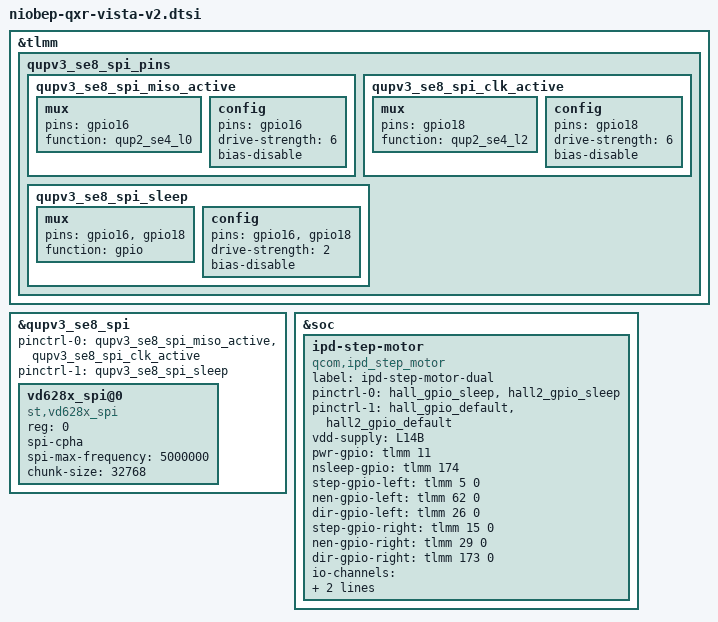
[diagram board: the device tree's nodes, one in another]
#include "niobep-qxr-vista.dtsi"

&tlmm {

	/delete-node/ qupv3_se8_spi_pins;

	qupv3_se8_spi_pins: qupv3_se8_spi_pins {
		qupv3_se8_spi_miso_active: qupv3_se8_spi_miso_active {
			mux {
				pins = "gpio16";
				function = "qup2_se4_l0";
			};

			config {
				pins = "gpio16";
				drive-strength = <6>;
				bias-disable;
			};
		};

		qupv3_se8_spi_clk_active: qupv3_se8_spi_clk_active {
			mux {
				pins = "gpio18";
				function = "qup2_se4_l2";
			};

			config {
				pins = "gpio18";
				drive-strength = <6>;
				bias-disable;
			};
		};

		qupv3_se8_spi_sleep: qupv3_se8_spi_sleep {
			mux {
				pins = "gpio16","gpio18";
				function = "gpio";
			};

			config {
				pins = "gpio16","gpio18";
				drive-strength = <2>;
				bias-disable;
			};
		};
	};
};

&qupv3_se8_spi {
	/delete-property/ pinctrl-1;
	/delete-property/ pinctrl-0;
	pinctrl-0 = <&qupv3_se8_spi_miso_active>, <&qupv3_se8_spi_clk_active>;
	pinctrl-1 = <&qupv3_se8_spi_sleep>;
};
&soc {
	/delete-node/ ipd-step-motor;

	ipd-step-motor {
		status = "ok";
		compatible = "qcom,ipd_step_motor";
		label = "ipd-step-motor-dual";

		pinctrl-names = "sleep", "default";
		pinctrl-0 = <&hall_gpio_sleep &hall2_gpio_sleep>;
		pinctrl-1 = <&hall_gpio_default &hall2_gpio_default>;
		vdd-supply = <&L14B>;

		pwr-gpio = <&tlmm 11  0>;
		nsleep-gpio = <&tlmm 174  0>;

		step-gpio-left = <&tlmm 5  0>;
		nen-gpio-left = <&tlmm 62 0>;
		dir-gpio-left = <&tlmm  26 0>;

		step-gpio-right = <&tlmm 15  0>;
		nen-gpio-right = <&tlmm 29 0>;
		dir-gpio-right = <&tlmm  173 0>;

		io-channels = <&pmk8550_vadc PMXR2230_ADC5_GEN3_AMUX_THM5>,
			<&pmk8550_vadc PMXR2230_ADC5_GEN3_AMUX_THM4>;
		io-channel-names = "ipd_step_motor_left",
			"ipd_step_motor_right";
	};
};

&qupv3_se8_spi {
	status = "ok";
	vd628x_spi@0 {
		compatible = "st,vd628x_spi";
		reg = <0>;
		spi-cpha;
		spi-max-frequency = <5000000>;
		chunk-size = <32768>;
		status = "ok";
	};
};
